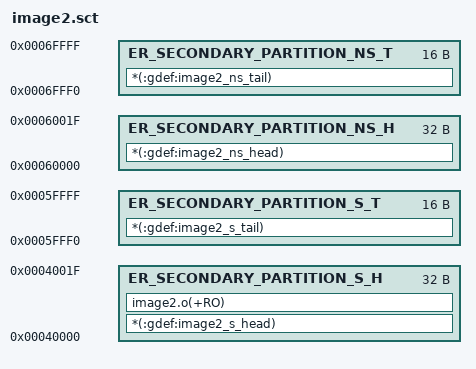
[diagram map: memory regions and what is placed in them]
LR_SECONDARY_PARTITION_S_H 0x40000 {
    ER_SECONDARY_PARTITION_S_H 0x40000 32 {
      *(:gdef:image2_s_head)
      image2.o(+RO)
    }
}
LR_SECONDARY_PARTITION_S_T 0x5FFF0 {
    ER_SECONDARY_PARTITION_S_T 0x5FFF0 16 {
      *(:gdef:image2_s_tail)
    }
}

LR_SECONDARY_PARTITION_NS_H 0x60000 {
    ER_SECONDARY_PARTITION_NS_H 0x60000 32 {
      *(:gdef:image2_ns_head)
    }
}
LR_SECONDARY_PARTITION_NS_T 0x6FFF0 {
    ER_SECONDARY_PARTITION_NS_T 0x6FFF0 16 {
      *(:gdef:image2_ns_tail)
    }
}
